# WE2_S_NS register map
Vendor: ARM Ltd.; Series: ARMv8.1-M Mainline; File version: 1.0
CPU: CM55 r1p1, little endian, MPU, FPU, double-precision FPU, DSP, VTOR, 3 interrupt priority bits
Registers are 32-bit, read-write, reset 0x0 unless marked. A register's access mark holds for its fields unless they carry their own. Offsets are from the block's base; [hi:lo] are bit positions; {n}, {i} and the like mark numbered series.

## SWREG_AON
Base 0x5610F000
Same registers: SWREG_AON_NS 0x4610F000
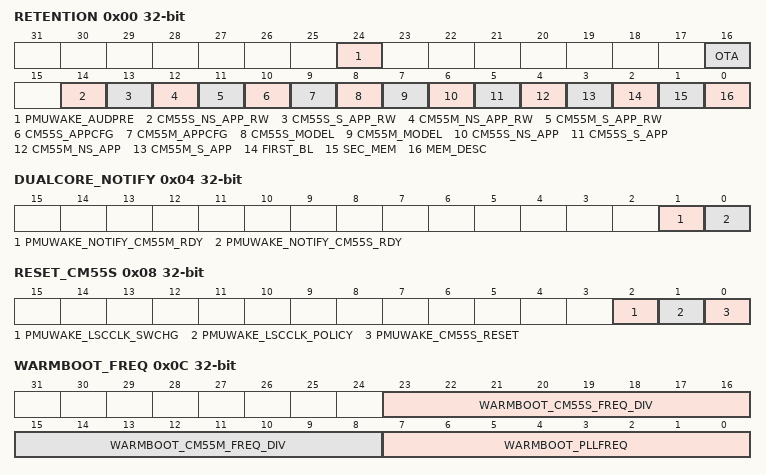
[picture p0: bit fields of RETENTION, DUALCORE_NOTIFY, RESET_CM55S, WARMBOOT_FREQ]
0x00 RETENTION
  [24] PMUWAKE_AUDPRE, [16] OTA, [14] CM55S_NS_APP_RW, [13] CM55S_S_APP_RW, [12] CM55M_NS_APP_RW, [11] CM55M_S_APP_RW, [10] CM55S_APPCFG, [9] CM55M_APPCFG, [8] CM55S_MODEL, [7] CM55M_MODEL, [6] CM55S_NS_APP, [5] CM55S_S_APP, [4] CM55M_NS_APP, [3] CM55M_S_APP, [2] FIRST_BL, [1] SEC_MEM, [0] MEM_DESC
0x04 DUALCORE_NOTIFY
  [1] PMUWAKE_NOTIFY_CM55M_RDY, [0] PMUWAKE_NOTIFY_CM55S_RDY
0x08 RESET_CM55S
  [2] PMUWAKE_LSCCLK_SWCHG, [1] PMUWAKE_LSCCLK_POLICY, [0] PMUWAKE_CM55S_RESET
0x0C WARMBOOT_FREQ
  [23:16] WARMBOOT_CM55S_FREQ_DIV, [15:8] WARMBOOT_CM55M_FREQ_DIV, [7:0] WARMBOOT_PLLFREQ
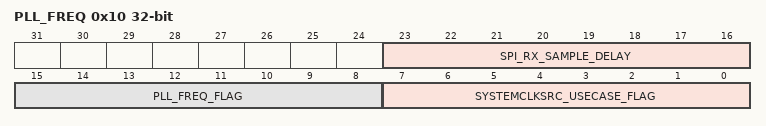
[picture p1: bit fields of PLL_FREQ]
0x10 PLL_FREQ
  [23:16] SPI_RX_SAMPLE_DELAY, [15:8] PLL_FREQ_FLAG, [7:0] SYSTEMCLKSRC_USECASE_FLAG
0x14 SW_STATUS
0x18 PLLFREQ

## TIMER0
Base 0x5500A000
Same registers: TIMER0_NS 0x4500A000, TIMER1_NS 0x4500B000, TIMER2_NS 0x4500C000, TIMER3_NS 0x4500D000, TIMER4_NS 0x4500E000, TIMER5_NS 0x4500F000, TIMER6_NS 0x46009000, TIMER7_NS 0x4600A000, TIMER8_NS 0x4600B000, TIMER1 0x5500B000, TIMER2 0x5500C000, TIMER3 0x5500D000, TIMER4 0x5500E000, TIMER5 0x5500F000, TIMER6 0x56009000, TIMER7 0x5600A000, TIMER8 0x5600B000
0x00 CTRL — Control Register (R/W)
0x04 VALUE — Current Value Register (R/W)
0x08 RELOAD — Reload Value Register (R/W)
0x0C INTSTATUS — Interrupt Status Register. Read Status and Write to Clear

## TPG
Base 0x55004600
Same registers: TPG_NS 0x45004600
0x00 TPG_EN_RST
0x04 TPG_CH123_DE_EMP_RDY
0x08 TPG_TG_V_POLMSWH
0x0C TPG_TG_V_FPSYBP
0x10 TPG_TG_V_AC
0x14 TPG_TG_H_POL
0x18 TPG_TG_H_FPSYBP
0x1C TPG_TG_H_AC
0x20 TPG_TG_SEL_DERGMS
{0x20+4i} TPG_CH{i}_PGSEL_MS_VAL (i=1..3)
0x30 TPG_FRAMEND

## UART0
Base 0x54003000
Same registers: UART1_NS 0x42000000, UART0_NS 0x44003000, UART2_NS 0x44004000, UART1 0x52000000, UART2 0x54004000
0x00 DATA — data in/out and DLL
0x04 IER — Interrupt enable register and DLH
0x08 IIR — Interrupt Id register and FCR
0x0C LCR — Line control Register
0x10 MCR — Modem control register
0x14 LSR — Line Status Register
0x18 MSR — Modem status Register
0x1C SCRATCHPAD — Uart scratch pad register
0x20 LPDLL — Low Power Divisor Latch (Low) Reg
0x24 LPDLH — Low Power Divisor Latch (High) Reg
0x28 RES1_0
0x2C RES1_1
{0x30+4i} SHR{i} (i=0..15) — Shadow data register(SRBR and STHR)
0x70 FAR — FIFO Access register
0x74 TFR — Transmit FIFO Read
0x78 RFW — Receive FIFO level
0x7C USR — UART status register
0x80 TFL — Transmit FIFO level
0x84 RFL — Receive FIFO level
0x88 SRR — Software reset register
0x8C SRTS — Shadow request to send
0x90 SBCR — Shadow break control
0x94 SDMAM — Shadow DMA mode
0x98 SFE — Shadow FIFO enable
0x9C SRT — Shadow RCVR Trigger
0xA0 STET — Shadow TX empty register
0xA4 HTX — Halt TX
0xA8 DMASA — DMA Software ACK
0xAC TCR — Transceiver Control Register
0xB0 DE_EN — Driver Output Enable Register
0xB4 RE_EN — Receiver Output Enable Register
0xB8 DET — Driver Output Enable Timing Register
0xBC TAT — TurnAround Timing Register
0xC0 DLF — Divisor Latch Fraction Register
0xF4 CPR — Camponent parameter register
0xF8 UCV — UART Component Version
0xFC CTR — Component typw register

## VAD
Base 0x52009F00
Same registers: VAD_NS 0x42009F00
0x00 int_en
0x04 int_mask
0x08 int_clr
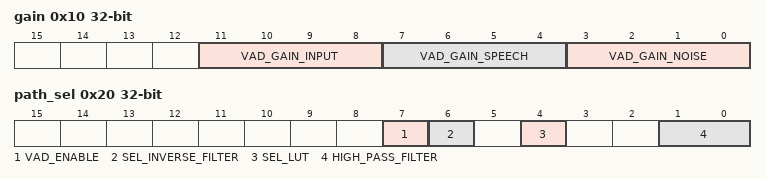
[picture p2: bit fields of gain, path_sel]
0x10 gain
  [11:8] VAD_GAIN_INPUT — Unsigned Gain value of the noise estimation
  [7:4] VAD_GAIN_SPEECH — Unsigned Gain value of the speech estimation
  [3:0] VAD_GAIN_NOISE — Unsigned Amplify pcm by shift (reg_gain_input-5) bits
0x14 lut_cmd
0x20 path_sel
  [7] VAD_ENABLE — VAD IP enable
  [6] SEL_INVERSE_FILTER — Select inverse filter. 0: no bypass, 1: bypass
  [4] SEL_LUT — Select LUT . 0 : no bypass, 1: bypass
  [1:0] HIGH_PASS_FILTER — Select high-pass filter. 0x00 or 0x03: bypass, 0x01: cutoff 2k @ 16k fs, 0x02: cutoff 1k @ 16k fs
0x24 alg_ctrl
0x28 k_noise
0x40 debug_sel
0x44 debug_data

## WDT0
Base 0x55000000
Same registers: WDT0_NS 0x45000000, WDT1_NS 0x45001000, WDT1 0x55001000
0x00 LOAD — Watchdog Load Register
0x04 VALUE — Watchdog Value Register
0x08 CTRL — Watchdog Control Register [0] INTEN: Interrupt enable [1] RESEN: Reset enable
0x0C INTCLR — Watchdog Clear Interrupt Register
0x10 RAWINTSTAT — Watchdog Raw Interrupt Status Register
0x14 MASKINTSTAT — Watchdog Interrupt Status Register
0xC00 LOCK — Watchdog Lock Register
0xF00 ITCR — Watchdog Integration Test Control Register
0xF04 ITOP — Watchdog Integration Test Output Set Register

## XDMA
Base 0x55004700
Same registers: XDMA_NS 0x45004700
0x00 xDMA_WDMA123_RDMA_En
0x04 xDMA_WDMA12_MSK
0x08 xDMA_WDMA3_RDMA_MSK
0x0C xDMA_WDMA12_status
0x10 xDMA_WDMA3_RDMA_status
0x14 xDMA_WDMA123_RDMA_irqc
0x18 xDMA_WDMA_RESERVED_18
0x1C xDMA_WDMA_RESERVED_1C
0x20 xDMA_WDMA1_Chn_En_Mode
{0x1C+8i} xDMA_WDMA1_STARTADDR{i} (i=1..3)
{0x20+8i} xDMA_WDMA1_THR{i} (i=1..3)
0x3C xDMA_WDMA1_BURST_LEN
0x40 xDMA_WDMA2_DoneModeTGTCRT
0x44 xDMA_WDMA2_STARTADDR1
0x48 xDMA_WDMA2_THR1
0x4C xDMA_WDMA2_OFFSET
0x50 xDMA_WDMA2_crt_lp_out
0x54 xDNA_WDMA2_FILESIZE_STARTADDR
0x58 xDMA_WDMA2_BURST_LEN
0x5C xDMA_WDMA2_RESERVE3
0x60 xDMA_WDMA3_Chn_En_Mode
{0x5C+8i} xDMA_WDMA3_STARTADDR{i} (i=1..3)
{0x60+8i} xDMA_WDMA3_THR{i} (i=1..3)
0x7C xDMA_WDMA3_BURST_LEN
0x80 xDMA_RDMA_Chn_En_Mode
{0x7C+8i} xDMA_RDMA_STARTADDR{i} (i=1..3)
{0x80+8i} xDMA_RDMA_THR{i} (i=1..3)
0x9C xDMA_RDMA_BURST_LEN

## ISP
Base 0x51010000
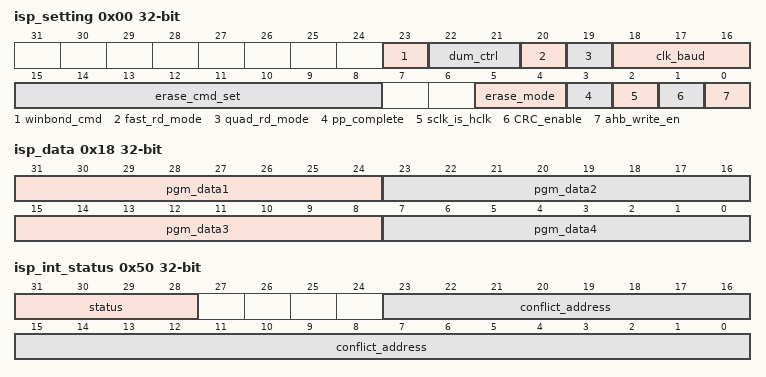
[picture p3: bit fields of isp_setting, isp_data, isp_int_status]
0x00 isp_setting
  [23] winbond_cmd — 0: Macronix mode. 1: Winbond mode
  [22:21] dum_ctrl — 0: 8 dummy cycles. 1: 6 dummy cycles. 2: 8 dummy cycles. 3: 10 dummy cycles
  [20] fast_rd_mode — 1: enable fast read mode
  [19] quad_rd_mode — 1: enable quad read mode
  [18:16] clk_baud — [0] 2, [1] 4, [2] 6, [3] 8, [4] 10, [5] 12, [6] 14, [7] 16
  [15:8] erase_cmd_set — 1: enable FW cmd
  [5:4] erase_mode — 0: SE, 1: BE (32k), 2: BE(64k), 3: CE
  [3] pp_complete — 1: send intp when pp complete
  [2] sclk_is_hclk — 0: reference baud rate. 1: sclk / hclk = 1
  [1] CRC_enable — 0: CRC disable without read back. 1: CRC enable with read back
  [0] ahb_write_en — 0: AHB read. 1: AHB write
0x04 isp_crc_wout — irst wrong CRC result for write
0x08 isp_crc_rout — First wrong CRC result for read
0x10 isp_pgm_en — [0] 0: disable programmable mode; 1: enable programmable mode
0x14 isp_pgm_ctrl
0x18 isp_data
  [39-8n:32-8n] pgm_data{n} (n=1..4)
0x30 isp_rst_crc_info — If read, it will reset the CRC_wout, CRC_rout and CRC_conflict_addr to 0
0x50 isp_int_status
  [31:28] status — 0: no interrupt, 1: CRC intp, 2: page program complete intp, 3: CRC and pp_complete intp
  [23:0] conflict_address
